VERSION ""

BU_: ECU Receiver

//1+がリトルエンディアン0+がビッグエンディアン
//0+にすると警告が出る
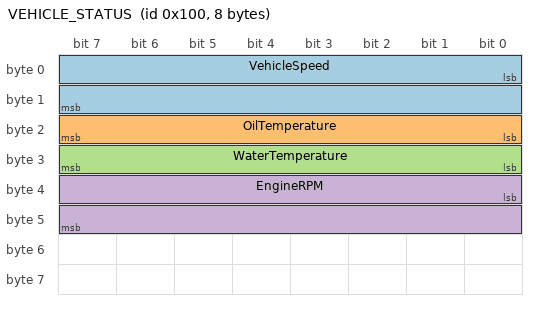
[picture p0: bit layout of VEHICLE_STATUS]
BO_ 256 VEHICLE_STATUS: 8 ECU

SG_ VehicleSpeed   : 0|16@1+ (0.1,0) [0|250] "km/h" Receiver
SG_ OilTemperature : 16|8@1+ (1,0) [-40|200] "degC" Receiver
SG_ WaterTemperature : 24|8@1+ (1,0) [-40|200] "degC" Receiver
SG_ EngineRPM : 32|16@1+ (1,0) [0|8000] "rpm" Receiver
